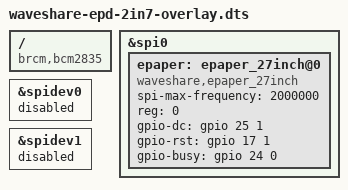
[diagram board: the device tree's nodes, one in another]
/*
 * Device Tree overlay for Waveshare 2.7 inch ePaper Display
 *
 */

/dts-v1/;
/plugin/;

/ {
	compatible = "brcm,bcm2835", "brcm,bcm2708";


	fragment@0 {
		target = <&spi0>;
		__overlay__ {
			status = "okay";
		};
	};

	fragment@1 {
		target = <&spidev0>;
		__overlay__ {
			status = "disabled";
		};
	};

	fragment@2 {
		target = <&spidev1>;
		__overlay__ {
			status = "disabled";
		};
	};

	fragment@3 {
		target = <&spi0>;
		__overlay__ {
			/* needed to avoid dtc warning */
			#address-cells = <1>;
			#size-cells = <0>;

			epaper: epaper_27inch@0 {
				compatible = "waveshare,epaper_27inch";
				spi-max-frequency = <2000000>;
				reg = <0>;
				gpio-dc = <&gpio 25 1>;
				gpio-rst = <&gpio 17 1>;
				gpio-busy = <&gpio 24 0>;
			};
		};
	};
};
